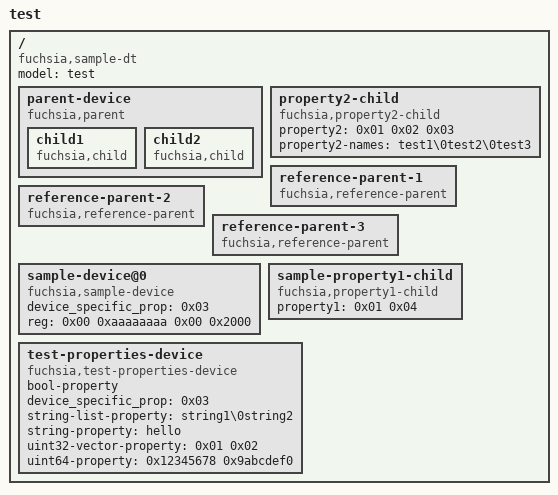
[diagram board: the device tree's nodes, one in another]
/dts-v1/;

/ {
	#address-cells = <0x02>;
	#size-cells = <0x02>;
	compatible = "fuchsia,sample-dt";
	model = "test";

	parent-device {
		compatible = "fuchsia,parent";

		child1 {
			compatible = "fuchsia,child";
		};

		child2 {
			compatible = "fuchsia,child";
		};
	};

	property2-child {
		compatible = "fuchsia,property2-child";
		property2 = <0x01 0x02 0x03>;
		property2-names = "test1\0test2\0test3";
	};

	reference-parent-1 {
		#property1-cells = <0x01>;
		#property2-cells = <0x00>;
		compatible = "fuchsia,reference-parent";
		phandle = <0x01>;
	};

	reference-parent-2 {
		#property2-cells = <0x00>;
		compatible = "fuchsia,reference-parent";
		phandle = <0x02>;
	};

	reference-parent-3 {
		#property2-cells = <0x00>;
		compatible = "fuchsia,reference-parent";
		phandle = <0x03>;
	};

	sample-device@0 {
		compatible = "fuchsia,sample-device";
		device_specific_prop = <0x03>;
		reg = <0x00 0xaaaaaaaa 0x00 0x2000>;
	};

	sample-property1-child {
		compatible = "fuchsia,property1-child";
		property1 = <0x01 0x04>;
	};

	test-properties-device {
		bool-property;
		compatible = "fuchsia,test-properties-device";
		device_specific_prop = <0x03>;
		string-list-property = "string1\0string2";
		string-property = "hello";
		uint32-vector-property = <0x01 0x02>;
		uint64-property = <0x12345678 0x9abcdef0>;
	};
};
